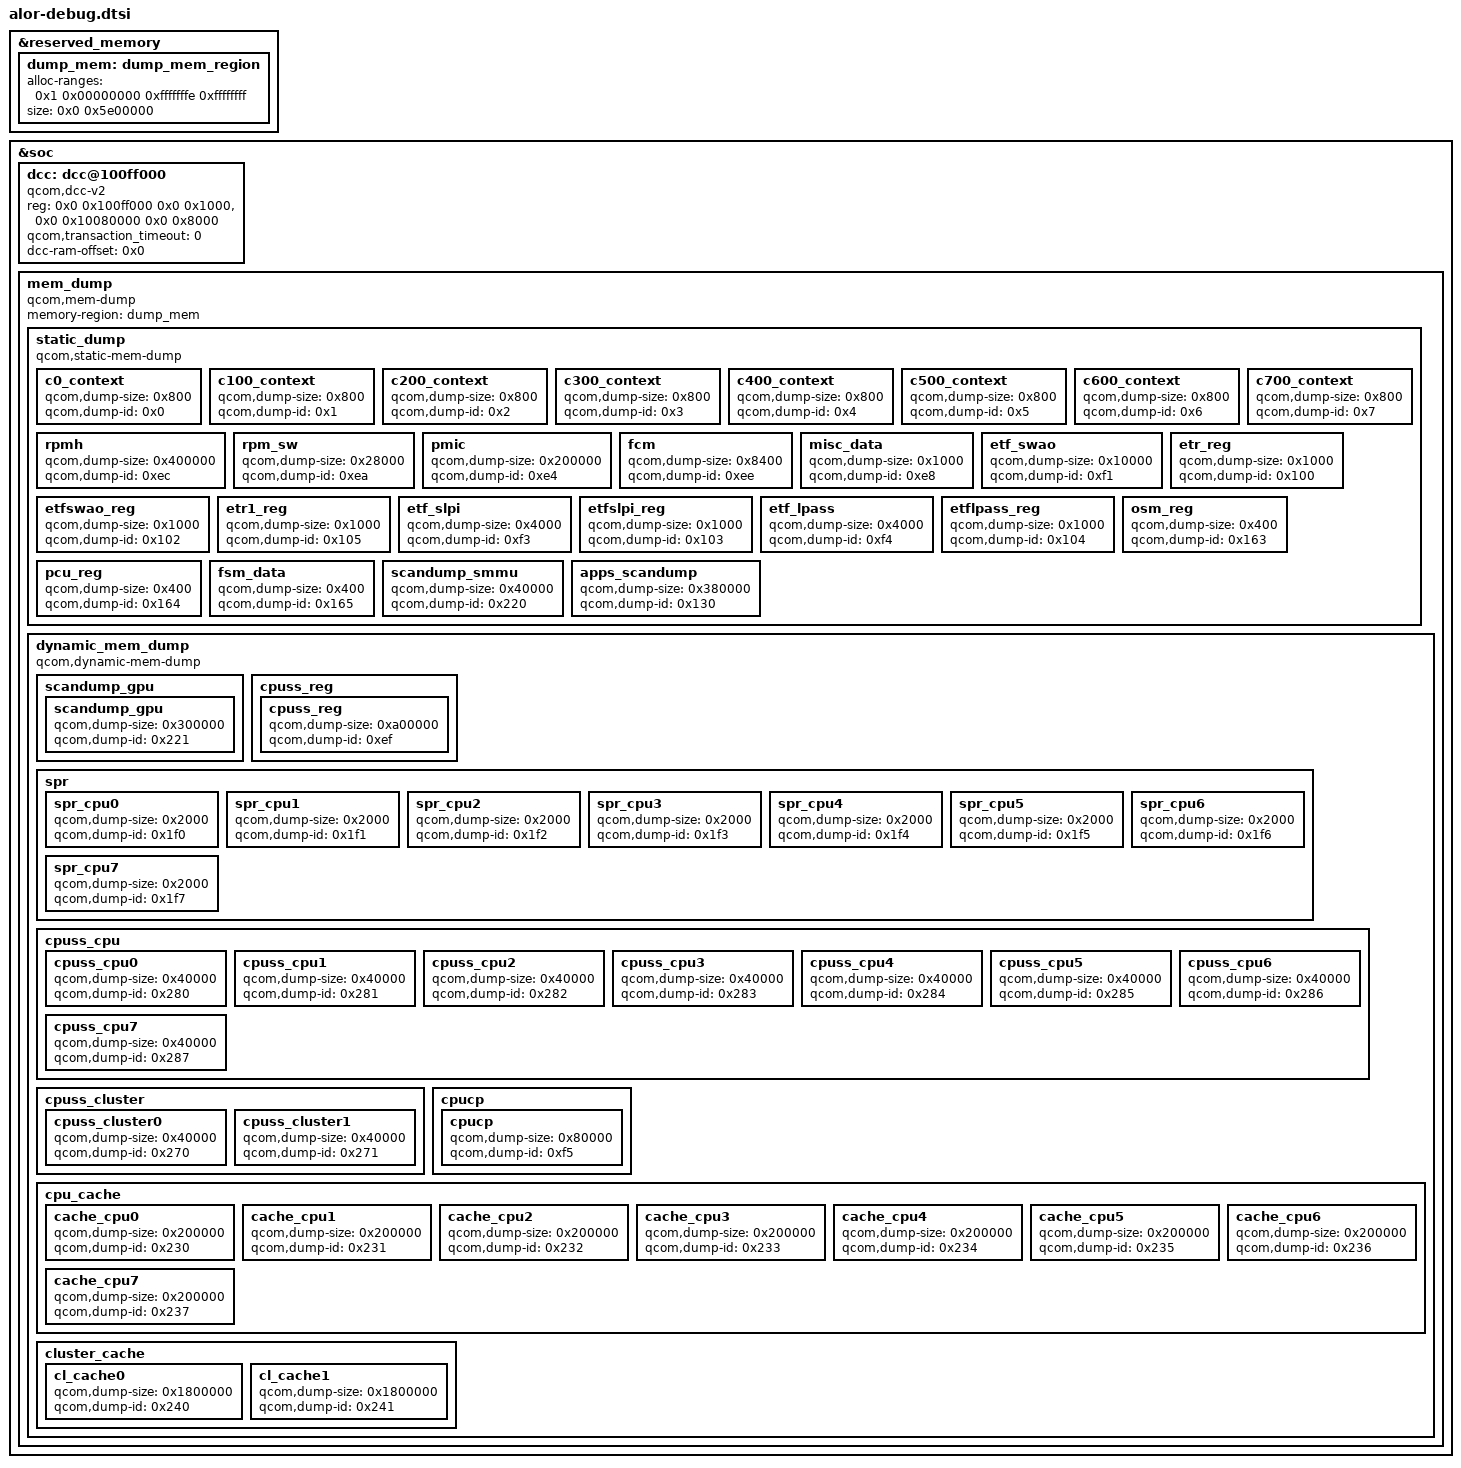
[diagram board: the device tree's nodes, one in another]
// SPDX-License-Identifier: BSD-3-Clause
/*
 * Copyright (c) Qualcomm Technologies, Inc. and/or its subsidiaries.
 */

 #include <dt-bindings/soc/qcom,dcc_v2.h>

&reserved_memory {
	#address-cells = <2>;
	#size-cells = <2>;
	ranges;

	dump_mem: dump_mem_region {
		alloc-ranges = <0x1 0x00000000 0xfffffffe 0xffffffff>;
		size = <0x0 0x5e00000>;
	};
};

&soc {
	dcc: dcc@100ff000 {
		compatible = "qcom,dcc-v2";
		reg = <0x0 0x100ff000 0x0 0x1000>,
		      <0x0 0x10080000 0x0 0x8000>;
		reg-names = "dcc-base", "dcc-ram-base";

		qcom,transaction_timeout = <0>;
		dcc-ram-offset = <0x0>;
	};

	mem_dump {
		compatible = "qcom,mem-dump";
		memory-region = <&dump_mem>;

		static_dump {
			qcom,static-mem-dump;

			c0_context {
				qcom,dump-size = <0x800>;
				qcom,dump-id = <0x0>;
			};

			c100_context {
				qcom,dump-size = <0x800>;
				qcom,dump-id = <0x1>;
			};

			c200_context {
				qcom,dump-size = <0x800>;
				qcom,dump-id = <0x2>;
			};

			c300_context {
				qcom,dump-size = <0x800>;
				qcom,dump-id = <0x3>;
			};

			c400_context {
				qcom,dump-size = <0x800>;
				qcom,dump-id = <0x4>;
			};

			c500_context {
				qcom,dump-size = <0x800>;
				qcom,dump-id = <0x5>;
			};

			c600_context {
				qcom,dump-size = <0x800>;
				qcom,dump-id = <0x6>;
			};

			c700_context {
				qcom,dump-size = <0x800>;
				qcom,dump-id = <0x7>;
			};

			rpmh {
				qcom,dump-size = <0x400000>;
				qcom,dump-id = <0xec>;
			};

			rpm_sw {
				qcom,dump-size = <0x28000>;
				qcom,dump-id = <0xea>;
			};

			pmic {
				qcom,dump-size = <0x200000>;
				qcom,dump-id = <0xe4>;
			};

			fcm {
				qcom,dump-size = <0x8400>;
				qcom,dump-id = <0xee>;
			};

			misc_data {
				qcom,dump-size = <0x1000>;
				qcom,dump-id = <0xe8>;
			};

			etf_swao {
				qcom,dump-size = <0x10000>;
				qcom,dump-id = <0xf1>;
			};

			etr_reg {
				qcom,dump-size = <0x1000>;
				qcom,dump-id = <0x100>;
			};

			etfswao_reg {
				qcom,dump-size = <0x1000>;
				qcom,dump-id = <0x102>;
			};

			etr1_reg {
				qcom,dump-size = <0x1000>;
				qcom,dump-id = <0x105>;
			};

			etf_slpi {
				qcom,dump-size = <0x4000>;
				qcom,dump-id = <0xf3>;
			};

			etfslpi_reg {
				qcom,dump-size = <0x1000>;
				qcom,dump-id = <0x103>;
			};

			etf_lpass {
				qcom,dump-size = <0x4000>;
				qcom,dump-id = <0xf4>;
			};

			etflpass_reg {
				qcom,dump-size = <0x1000>;
				qcom,dump-id = <0x104>;
			};

			osm_reg {
				qcom,dump-size = <0x400>;
				qcom,dump-id = <0x163>;
			};

			pcu_reg {
				qcom,dump-size = <0x400>;
				qcom,dump-id = <0x164>;
			};

			fsm_data {
				qcom,dump-size = <0x400>;
				qcom,dump-id = <0x165>;
			};

			scandump_smmu {
				qcom,dump-size = <0x40000>;
				qcom,dump-id = <0x220>;
			};

			apps_scandump {
				qcom,dump-size = <0x380000>;
				qcom,dump-id = <0x130>;
			};
		};

		dynamic_mem_dump {
			qcom,dynamic-mem-dump;

			scandump_gpu {
				scandump_gpu {
					qcom,dump-size = <0x300000>;
					qcom,dump-id = <0x221>;
				};
			};

			cpuss_reg {
				cpuss_reg {
					qcom,dump-size = <0xa00000>;
					qcom,dump-id = <0xef>;
				};
			};

			spr {
				spr_cpu0 {
					qcom,dump-size = <0x2000>;
					qcom,dump-id = <0x1f0>;
				};

				spr_cpu1 {
					qcom,dump-size = <0x2000>;
					qcom,dump-id = <0x1f1>;
				};

				spr_cpu2 {
					qcom,dump-size = <0x2000>;
					qcom,dump-id = <0x1f2>;
				};

				spr_cpu3 {
					qcom,dump-size = <0x2000>;
					qcom,dump-id = <0x1f3>;
				};

				spr_cpu4 {
					qcom,dump-size = <0x2000>;
					qcom,dump-id = <0x1f4>;
				};

				spr_cpu5 {
					qcom,dump-size = <0x2000>;
					qcom,dump-id = <0x1f5>;
				};

				spr_cpu6 {
					qcom,dump-size = <0x2000>;
					qcom,dump-id = <0x1f6>;
				};

				spr_cpu7 {
					qcom,dump-size = <0x2000>;
					qcom,dump-id = <0x1f7>;
				};
			};

			cpuss_cpu {
				cpuss_cpu0 {
					qcom,dump-size = <0x40000>;
					qcom,dump-id = <0x280>;
				};

				cpuss_cpu1 {
					qcom,dump-size = <0x40000>;
					qcom,dump-id = <0x281>;
				};

				cpuss_cpu2 {
					qcom,dump-size = <0x40000>;
					qcom,dump-id = <0x282>;
				};

				cpuss_cpu3 {
					qcom,dump-size = <0x40000>;
					qcom,dump-id = <0x283>;
				};

				cpuss_cpu4 {
					qcom,dump-size = <0x40000>;
					qcom,dump-id = <0x284>;
				};

				cpuss_cpu5 {
					qcom,dump-size = <0x40000>;
					qcom,dump-id = <0x285>;
				};

				cpuss_cpu6 {
					qcom,dump-size = <0x40000>;
					qcom,dump-id = <0x286>;
				};

				cpuss_cpu7 {
					qcom,dump-size = <0x40000>;
					qcom,dump-id = <0x287>;
				};
			};

			cpuss_cluster {
				cpuss_cluster0 {
					qcom,dump-size = <0x40000>;
					qcom,dump-id = <0x270>;
				};

				cpuss_cluster1 {
					qcom,dump-size = <0x40000>;
					qcom,dump-id = <0x271>;
				};
			};

			cpucp {
				cpucp {
					qcom,dump-size = <0x80000>;
					qcom,dump-id = <0xf5>;
				};
			};

			cpu_cache {
				cache_cpu0 {
					qcom,dump-size = <0x200000>;
					qcom,dump-id = <0x230>;
				};

				cache_cpu1 {
					qcom,dump-size = <0x200000>;
					qcom,dump-id = <0x231>;
				};

				cache_cpu2 {
					qcom,dump-size = <0x200000>;
					qcom,dump-id = <0x232>;
				};

				cache_cpu3 {
					qcom,dump-size = <0x200000>;
					qcom,dump-id = <0x233>;
				};

				cache_cpu4 {
					qcom,dump-size = <0x200000>;
					qcom,dump-id = <0x234>;
				};

				cache_cpu5 {
					qcom,dump-size = <0x200000>;
					qcom,dump-id = <0x235>;
				};

				cache_cpu6 {
					qcom,dump-size = <0x200000>;
					qcom,dump-id = <0x236>;
				};

				cache_cpu7 {
					qcom,dump-size = <0x200000>;
					qcom,dump-id = <0x237>;
				};
			};

			cluster_cache {
				cl_cache0 {
					qcom,dump-size = <0x1800000>;
					qcom,dump-id = <0x240>;
				};

				cl_cache1 {
					qcom,dump-size = <0x1800000>;
					qcom,dump-id = <0x241>;
				};

			};
		};
	};
};
